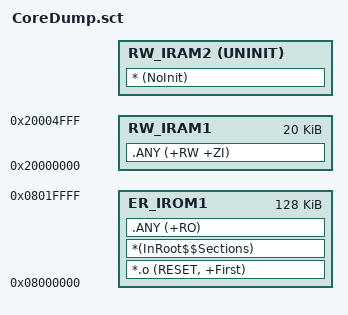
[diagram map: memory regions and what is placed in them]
; *************************************************************
; *** Scatter-Loading Description File generated by uVision ***
; *************************************************************

LR_IROM1 0x08000000 0x00020000  {    ; load region size_region
  ER_IROM1 0x08000000 0x00020000  {  ; load address = execution address
   *.o (RESET, +First)
   *(InRoot$$Sections)
   .ANY (+RO)
  }
  RW_IRAM1 0x20000000 0x00005000  {  ; RW data
   .ANY (+RW +ZI)
  }

  ; Create a section for uninitialized data. This prevents zero 
  ; initialized (ZI) data located in NoInit to persist over a CPU reset. 
  RW_IRAM2 +0 UNINIT {
    * (NoInit)
  }
}

